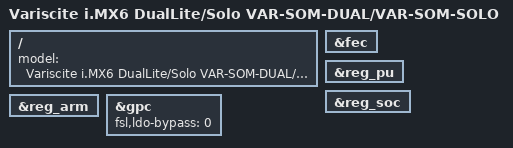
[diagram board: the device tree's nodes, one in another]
/*
 * Copyright (C) 2015-2017 Variscite Ltd.
 *
 * This program is free software; you can redistribute it and/or modify
 * it under the terms of the GNU General Public License version 2 as
 * published by the Free Software Foundation.
 */

#include "imx6dl-var-som.dtsi"

/ {
	model = "Variscite i.MX6 DualLite/Solo VAR-SOM-DUAL/VAR-SOM-SOLO";
};

&fec {
	/delete-property/ phy-reset-on-resume;
};

&reg_arm {
	/delete-property/ vin-supply;
};

&reg_pu {
	/delete-property/ vin-supply;
};

&reg_soc {
	/delete-property/ vin-supply;
};

&gpc {
	/* use ldo-enable, u-boot will check it and configure */
	fsl,ldo-bypass = <0>;
};
